# MB9BF16xx register map
File version: 1.0
Registers are 8-bit, read-write, reset 0x0 unless marked. A register's access mark holds for its fields unless they carry their own. Offsets are from the block's base; [hi:lo] are bit positions; {n}, {i} and the like mark numbered series.

## DAC0 — peripheral DAC0
Base 0x40033000
Same registers: DAC1 0x40033008
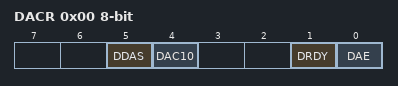
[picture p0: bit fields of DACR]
0x00 DACR
  [5] DDAS, [4] DAC10, [1] DRDY ro, [0] DAE
0x04 DADR 16-bit reset not defined
  [9:0] DA

## EXTI — peripheral EXTI
Base 0x40030000
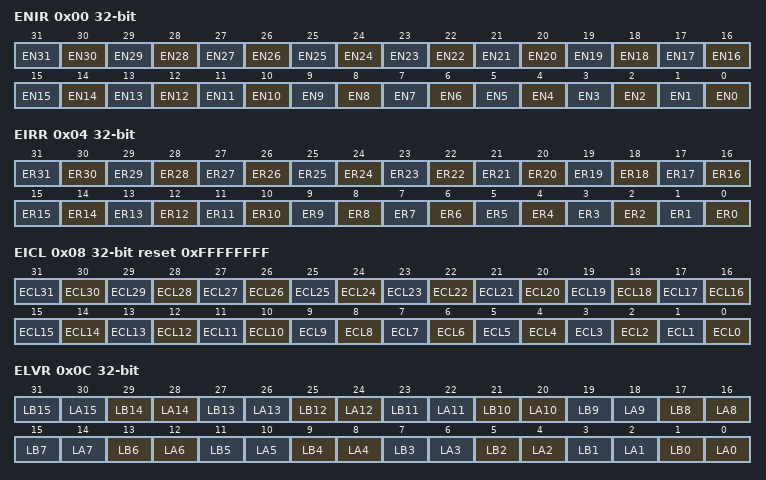
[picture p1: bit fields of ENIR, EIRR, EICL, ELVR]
0x00 ENIR 32-bit
  [n] EN{n} (n=0..31)
0x04 EIRR 32-bit ro reset not defined
  [n] ER{n} (n=0..31)
0x08 EICL 32-bit reset 0xFFFFFFFF
  [n] ECL{n} (n=0..31)
0x0C ELVR 32-bit
  [2n+1] LB{n} (n=0..15), [2n] LA{n} (n=0..15)
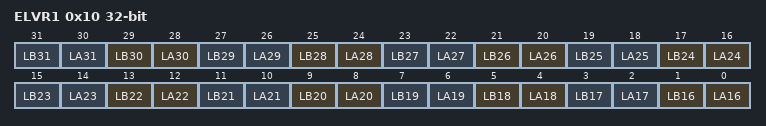
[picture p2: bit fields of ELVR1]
0x10 ELVR1 32-bit
  [2n-31] LB{n} (n=16..31), [2n-32] LA{n} (n=16..31)
0x14 NMIRR ro
  [0] NR
0x18 NMICL reset 0x1
  [0] NCL

## LVD — peripheral LVD
Base 0x40035000
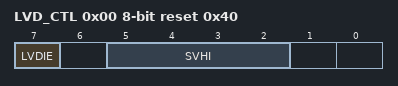
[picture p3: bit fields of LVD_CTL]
0x00 LVD_CTL reset 0x40
  [7] LVDIE, [5:2] SVHI
0x04 LVD_STR ro
  [7] LVDIR
0x08 LVD_CLR reset 0x80
  [7] LVDCL
0x0C LVD_RLR 32-bit reset 0x1
  [31:0] LVDLCK
0x10 LVD_STR2 ro reset 0x40
  [7] LVDIRDY

## DS — peripheral DS
Base 0x40035100
0x04 RCK_CTL reset 0x1
  [0] RTCCKE
0x700 PMD_CTL
  [0] RTCE
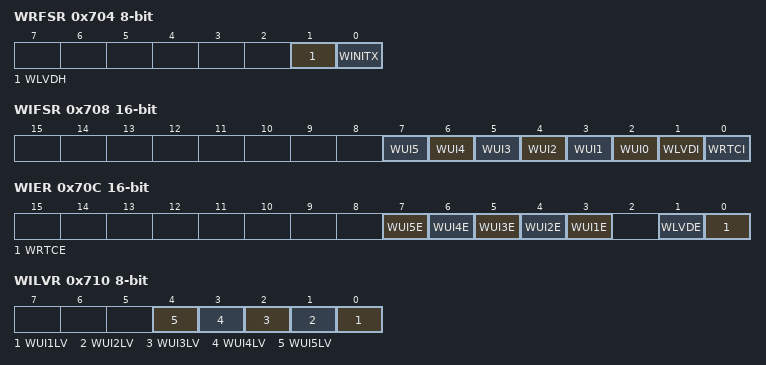
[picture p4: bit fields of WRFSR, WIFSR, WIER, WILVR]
0x704 WRFSR
  [1] WLVDH, [0] WINITX
0x708 WIFSR 16-bit ro
  [n+2] WUI{n} (n=0..5), [1] WLVDI, [0] WRTCI
0x70C WIER 16-bit
  [n+2] WUI{n}E (n=1..5), [1] WLVDE, [0] WRTCE
0x710 WILVR
  [n-1] WUI{n}LV (n=1..5)
0x714 DSRAMR
  [1:0] SRAMR
{0x7FF+i} BUR{i:02} (i=1..16)

## CRC — peripheral CRC
Base 0x40039000
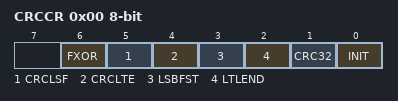
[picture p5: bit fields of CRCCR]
0x00 CRCCR
  [6] FXOR, [5] CRCLSF, [4] CRCLTE, [3] LSBFST, [2] LTLEND, [1] CRC32, [0] INIT
0x04 CRCINIT 32-bit reset 0xFFFFFFFF
  [31:0] D
0x08 CRCIN 32-bit
  [31:0] D
0x0C CRCR 32-bit ro reset 0xFFFFFFFF
  [31:0] D

## WC — peripheral WC
Base 0x4003A000
0x00 WCRD ro
  [5:0] CTR
0x01 WCRL
  [5:0] RLC
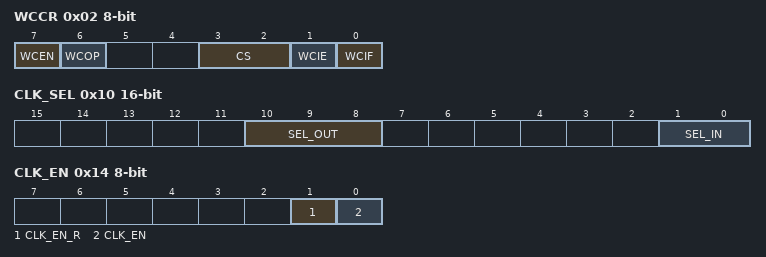
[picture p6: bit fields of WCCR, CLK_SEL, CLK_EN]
0x02 WCCR
  [7] WCEN, [6] WCOP ro, [3:2] CS, [1] WCIE, [0] WCIF
0x10 CLK_SEL 16-bit
  [10:8] SEL_OUT, [1:0] SEL_IN
0x14 CLK_EN
  [1] CLK_EN_R, [0] CLK_EN

## RTC — peripheral RTC
Base 0x4003B000
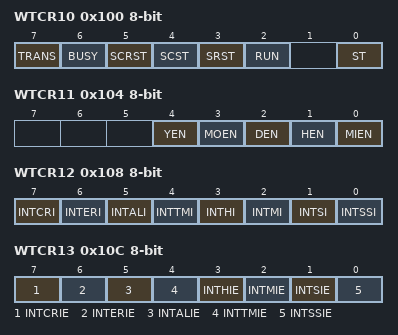
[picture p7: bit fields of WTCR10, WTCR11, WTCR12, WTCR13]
0x100 WTCR10
  [7] TRANS ro, [6] BUSY ro, [5] SCRST, [4] SCST, [3] SRST, [2] RUN ro, [0] ST
0x104 WTCR11
  [4] YEN, [3] MOEN, [2] DEN, [1] HEN, [0] MIEN
0x108 WTCR12
  [7] INTCRI, [6] INTERI, [5] INTALI, [4] INTTMI, [3] INTHI, [2] INTMI, [1] INTSI, [0] INTSSI
0x10C WTCR13
  [7] INTCRIE, [6] INTERIE, [5] INTALIE, [4] INTTMIE, [3] INTHIE, [2] INTMIE, [1] INTSIE, [0] INTSSIE
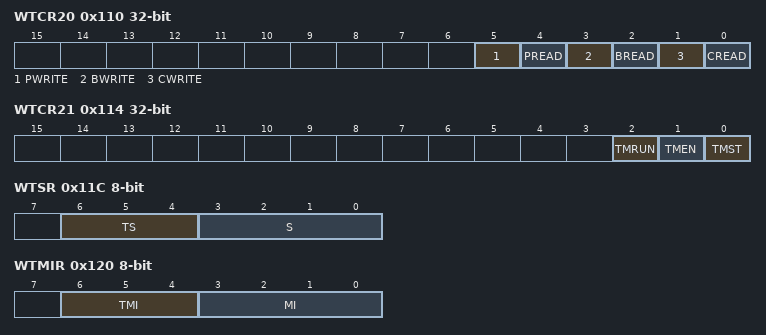
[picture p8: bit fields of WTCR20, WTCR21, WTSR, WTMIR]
0x110 WTCR20 32-bit
  [5] PWRITE, [4] PREAD, [3] BWRITE, [2] BREAD, [1] CWRITE, [0] CREAD
0x114 WTCR21 32-bit
  [2] TMRUN ro, [1] TMEN, [0] TMST
0x11C WTSR
  [6:4] TS, [3:0] S
0x120 WTMIR
  [6:4] TMI, [3:0] MI
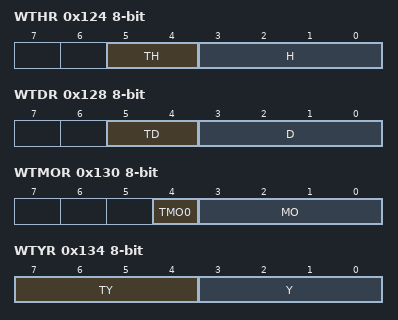
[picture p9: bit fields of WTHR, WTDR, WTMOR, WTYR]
0x124 WTHR
  [5:4] TH, [3:0] H
0x128 WTDR
  [5:4] TD, [3:0] D
0x12C WTDW
  [2:0] DW
0x130 WTMOR
  [4] TMO0, [3:0] MO
0x134 WTYR
  [7:4] TY, [3:0] Y
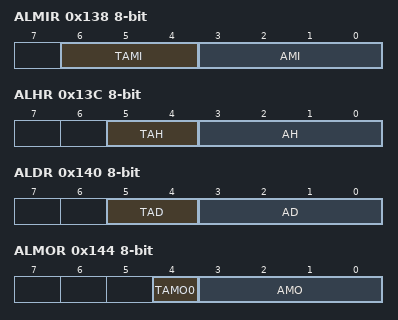
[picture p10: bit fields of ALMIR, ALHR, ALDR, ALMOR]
0x138 ALMIR
  [6:4] TAMI, [3:0] AMI
0x13C ALHR
  [5:4] TAH, [3:0] AH
0x140 ALDR
  [5:4] TAD, [3:0] AD
0x144 ALMOR
  [4] TAMO0, [3:0] AMO
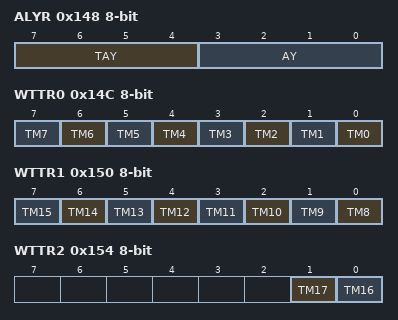
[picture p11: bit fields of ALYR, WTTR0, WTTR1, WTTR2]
0x148 ALYR
  [7:4] TAY, [3:0] AY
0x14C WTTR0
  [n] TM{n} (n=0..7)
0x150 WTTR1
  [n-8] TM{n} (n=8..15)
0x154 WTTR2
  [1] TM17, [0] TM16
0x158 WTCAL0
0x15C WTCAL1
  [1:0] WTCAL1
0x160 WTCALEN
  [0] WTCALEN
0x164 WTDIV
  [3:0] WTDIV
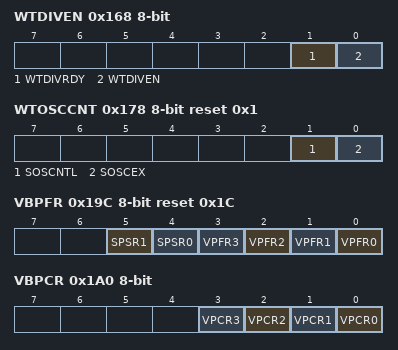
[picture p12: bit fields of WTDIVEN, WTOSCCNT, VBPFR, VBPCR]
0x168 WTDIVEN
  [1] WTDIVRDY ro, [0] WTDIVEN
0x16C WTCALPRD reset 0x13
  [5:0] WTCALPRD
0x170 WTCOSEL
  [0] WTCOSEL
0x174 VB_CLKDIV reset 0x7
  [7:0] DIV
0x178 WTOSCCNT reset 0x1
  [1] SOSCNTL, [0] SOSCEX
0x17C CCS reset 0x8
0x180 CCB reset 0x10
0x184 TRIM
0x188 BOOST reset 0x3
  [1:0] BOOST
0x18C EWKUP
  [0] WUP0
0x190 VDET reset 0x80
  [7] PON
0x194 FDET (reset mask 0x80)
0x198 HIBRST
  [0] HIBRST
0x19C VBPFR reset 0x1C
  [5] SPSR1, [4] SPSR0, [n] VPFR{n} (n=0..3)
0x1A0 VBPCR
  [n] VPCR{n} (n=0..3)
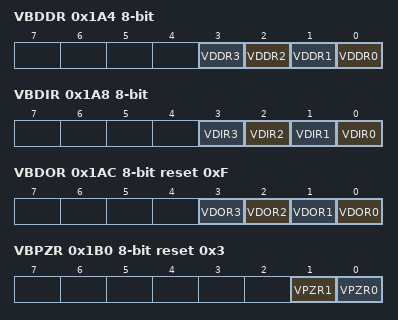
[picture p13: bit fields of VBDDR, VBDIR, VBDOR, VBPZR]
0x1A4 VBDDR
  [n] VDDR{n} (n=0..3)
0x1A8 VBDIR
  [n] VDIR{n} (n=0..3)
0x1AC VBDOR reset 0xF
  [n] VDOR{n} (n=0..3)
0x1B0 VBPZR reset 0x3
  [1] VPZR1, [0] VPZR0
{0x200+i} BREG{i:02} (i=0..9)
{0x20A+0x10*i} BREG{i}A (i=0..7)
{0x20B+0x10*i} BREG{i}B (i=0..7)
{0x20C+0x10*i} BREG{i}C (i=0..7)
{0x20D+0x10*i} BREG{i}D (i=0..7)
{0x20E+0x10*i} BREG{i}E (i=0..7)
{0x20F+0x10*i} BREG{i}F (i=0..7)
{0x206+i} BREG{i} (i=10..19)
{0x20C+i} BREG{i} (i=20..29)
{0x212+i} BREG{i} (i=30..39)
{0x218+i} BREG{i} (i=40..49)
{0x21E+i} BREG{i} (i=50..59)
{0x224+i} BREG{i} (i=60..69)
{0x22A+i} BREG{i} (i=70..79)

## LCR — peripheral LCR
Base 0x4003C000
0x00 LCR_PRSLD
  [5:0] LCR_PRSLD

## CLK_GATING — peripheral CLK_GATING
Base 0x4003C100
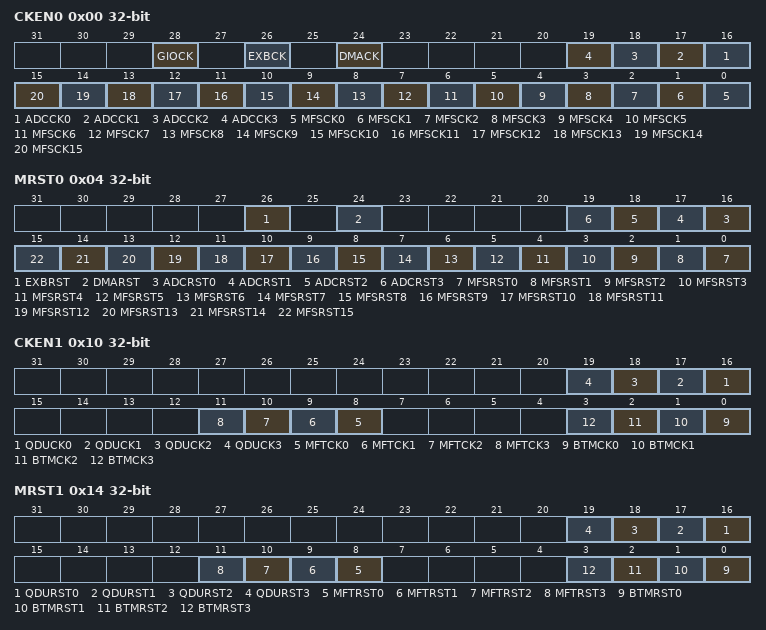
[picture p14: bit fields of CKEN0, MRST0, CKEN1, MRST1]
0x00 CKEN0 32-bit
  [28] GIOCK, [26] EXBCK, [24] DMACK, [n+16] ADCCK{n} (n=0..3), [n] MFSCK{n} (n=0..15)
0x04 MRST0 32-bit reset not defined
  [26] EXBRST, [24] DMARST, [n+16] ADCRST{n} (n=0..3), [n] MFSRST{n} (n=0..15)
0x10 CKEN1 32-bit
  [n+16] QDUCK{n} (n=0..3), [n+8] MFTCK{n} (n=0..3), [n] BTMCK{n} (n=0..3)
0x14 MRST1 32-bit reset not defined
  [n+16] QDURST{n} (n=0..3), [n+8] MFTRST{n} (n=0..3), [n] BTMRST{n} (n=0..3)
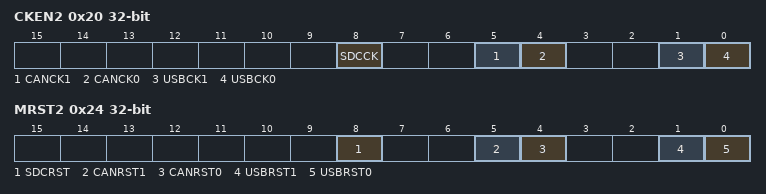
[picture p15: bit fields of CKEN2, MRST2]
0x20 CKEN2 32-bit (reset mask 0x30)
  [8] SDCCK, [5] CANCK1, [4] CANCK0, [1] USBCK1, [0] USBCK0
0x24 MRST2 32-bit reset not defined
  [8] SDCRST, [5] CANRST1, [4] CANRST0, [1] USBRST1, [0] USBRST0

## PLL_CONTROL — peripheral PLL_CONTROL
Base 0x4003C800
0x00 SSCTL1 32-bit (reset mask 0x31)
0x04 SSCTL2 32-bit (reset mask 0x3FF)

## EXBUS — peripheral EXBUS
Base 0x4003F000
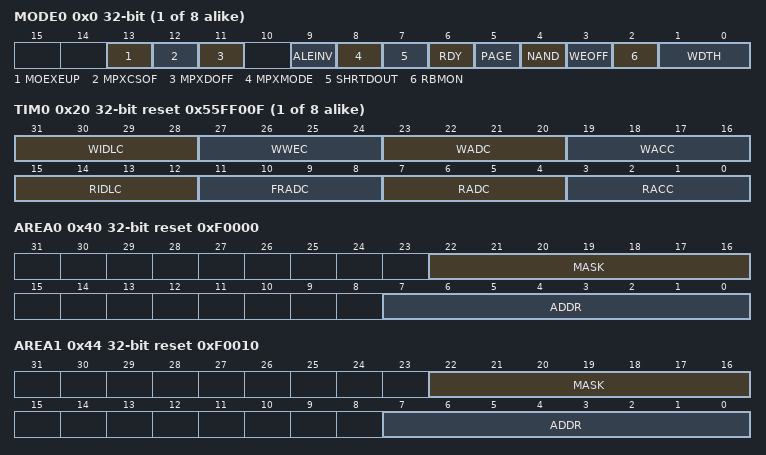
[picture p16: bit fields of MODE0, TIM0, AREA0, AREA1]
{0x0+4i} MODE{i} 32-bit (i=0..7)
  [13] MOEXEUP, [12] MPXCSOF, [11] MPXDOFF, [9] ALEINV, [8] MPXMODE, [7] SHRTDOUT, [6] RDY, [5] PAGE, [4] NAND, [3] WEOFF, [2] RBMON, [1:0] WDTH
{0x20+4i} TIM{i} 32-bit reset 0x55FF00F (i=0..7)
  [31:28] WIDLC, [27:24] WWEC, [23:20] WADC, [19:16] WACC, [15:12] RIDLC, [11:8] FRADC, [7:4] RADC, [3:0] RACC
0x40 AREA0 32-bit reset 0xF0000
  [22:16] MASK, [7:0] ADDR
0x44 AREA1 32-bit reset 0xF0010
  [22:16] MASK, [7:0] ADDR
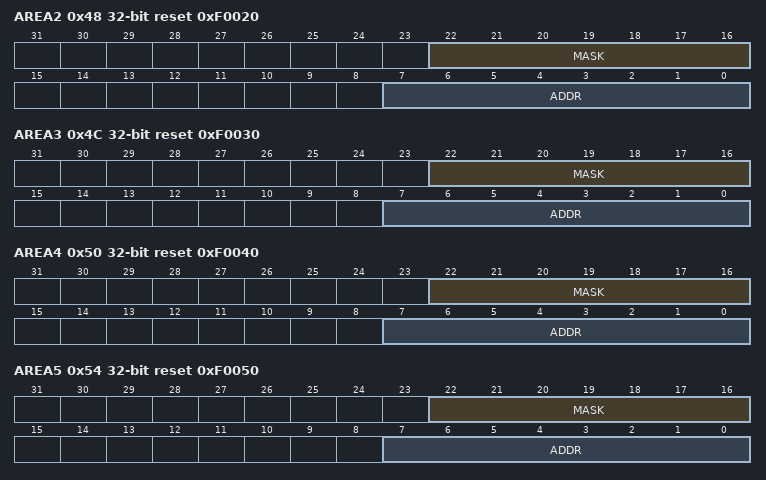
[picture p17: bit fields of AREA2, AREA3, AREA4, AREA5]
0x48 AREA2 32-bit reset 0xF0020
  [22:16] MASK, [7:0] ADDR
0x4C AREA3 32-bit reset 0xF0030
  [22:16] MASK, [7:0] ADDR
0x50 AREA4 32-bit reset 0xF0040
  [22:16] MASK, [7:0] ADDR
0x54 AREA5 32-bit reset 0xF0050
  [22:16] MASK, [7:0] ADDR
0x58 AREA6 32-bit reset 0xF0060
  [22:16] MASK, [7:0] ADDR
0x5C AREA7 32-bit reset 0xF0070
  [22:16] MASK, [7:0] ADDR
{0x60+4i} ATIM{i} 32-bit reset 0x45F (i=0..7)
  [11:8] ALEW, [7:4] ALES, [3:0] ALC
0x100 SMODE 32-bit reset 0x1300
  [16] MSDCLKOFF, [15:12] BASEL, [11:8] RASEL, [5:4] CASEL, [2] ROFF, [1] PDON, [0] SDON
0x104 REFTIM 32-bit reset 0x33
  [24] PREF, [23:16] NREF, [15:0] REFC
0x108 PWRDWN 32-bit
  [15:0] PDC
0x10C SDTIM 32-bit reset 0x420000
  [25:24] TDPL, [23:20] TREFC, [19:16] TRAS, [15:12] TRCD, [11:8] TRP, [7:4] TRC, [1:0] CL
0x110 SDCMD 32-bit
  [31] PEND ro, [20] SDCKE, [19] SDCS, [18] SDRAS, [17] SDCAS, [16] SDWE, [15:0] SDAD
0x200 MEMCERR 32-bit
  [3] SDION, [2] SFION, [1] SDER, [0] SFER
0x300 DCLKR 32-bit reset 0xF
  [4] MCLKON, [3:0] MDIV
0x304 EST 32-bit ro
  [0] WERR
0x308 WEAD 32-bit ro
  [31:0] ADDR
0x30C ESCLR 32-bit wo reset 0x1
  [0] WERRCLR
0x310 AMODE 32-bit reset 0x1
  [0] WAEN

## DMAC — peripheral DMAC
Base 0x40060000
0x00 DMACR 32-bit
  [31] DE, [30] DS, [28] PR, [27:24] DH
{0x10+0x10*i} DMACA{i} 32-bit (i=0..7)
  [31] EB, [30] PB, [29] ST, [28:23] IS, [19:16] BC, [15:0] TC
{0x14+0x10*i} DMACB{i} 32-bit (i=0..7)
  [29:28] MS, [27:26] TW, [25] FS, [24] FD, [23] RC, [22] RS, [21] RD, [20] EI, [19] CI, [18:16] SS, [0] EM
{0x18+0x10*i} DMACSA{i} 32-bit (i=0..7)
{0x1C+0x10*i} DMACDA{i} 32-bit (i=0..7)

## DSTC — peripheral DSTC
Base 0x40061000
0x00 DESTP 32-bit
0x04 HWDESP 32-bit
  [29:16] HWDESP, [7:0] CHANNEL
0x08 CMD reset 0x1
0x09 CFG reset 0x40
  [6:4] SWPR, [3] ESTE, [2] RBDIS, [1] ERINTE, [0] SWINTE
0x0A SWTR 16-bit
  [15] SWST ro, [14] SWREQ ro, [13:0] SWDESP
0x0C MONERS 32-bit
  [29:16] EDESP ro, [15:8] ECH ro, [6] EHS ro, [4] ESTOP ro, [3] DER ro, [2:0] EST ro
{0x10+4i} DREQENB{i} 32-bit (i=0..7)
{0x30+4i} HWINT{i} 32-bit (i=0..7)
{0x70+4i} DQMSK{i} 32-bit (i=0..7)
{0x90+4i} DQMSKCLR{i} 32-bit (i=0..7)

## SDIF — peripheral SDIF
Base 0x4006E000
0x00 DUMMY 32-bit reset not defined

## Notices in the file
Licence Terms
FUJITSU SEMICONDUCTOR LIMITED (gLICENSORh) hereby grants and
you (gLICENSEEh) hereby accept a non transferable, non-exclusive
licence to use and copy the deliverables (gDeliverablesh) solely for
the purpose of; (i) developing LICENSEEfs development tools and
distributing such development tools to third parties; (ii) generating
derivative representations of the Deliverables to develop and debug
software for LICENSORfs targeted devices or device series identified
within the Deliverables, (together the gPurposeh) under the following
terms and conditions:
1. Ownership.
The Deliverables are the property of LICENSOR. LICENSEE acquires no
right, title or interest in the Deliverables other than the licence
rights granted herein.
2. Use.
LICENSEE shall only be permitted to use the Deliverables for the
Purpose. LICENSEE shall not reverse engineer, decompile or
disassemble the Deliverables, in whole or in part.
3. Copies.
All copies of the Deliverables must bear the same notice(s) contained
on the original copies of the Deliverables.
4. No Warranty.
THE DELIVERABLES ARE PROVIDED gAS ISh AND ANY EXPRESS, IMPLIED OR
STATUTORY WARRANTIES, INCLUDING, BUT NOT LIMITED TO, THE IMPLIED
WARRANTIES OF MERCHANTABILITY, SATISFACTORY QUALITY AND FITNESS FOR
A PARTICULAR PURPOSE ARE DISCLAIMED.
IN NO EVENT SHALL LICENSOR BE LIABLE FOR ANY DIRECT, INDIRECT,
INCIDENTAL, SPECIAL, EXEMPLARY, OR CONSEQUENTIAL DAMAGES HOWEVER CAUSED
AND ON ANY THEORY OF LIABILITY, WHETHER IN CONTRACT, STRICT LIABILITY,
OR TORT (INCLUDING NEGLIGENCE OR OTHERWISE) ARISING IN ANY WAY OUT OF
THE USE OF THE DELIVERABLES, EVEN IF ADVISED OF THE POSSIBILITY OF SUCH
DAMAGE.
LICENSEE EXPRESSLY ASSUMES ALL LIABILITIES AND RISKS, FOR USE OR
OPERATION OF THE DELIVERABLES.
5.In the event that LICENSEE receives early access to the Deliverables,
LICENSEE acknowledges and agrees that;
(a) notwithstanding the licence grants above, LICENSEE shall only be
permitted to use the Deliverables solely internally for evaluation and
providing feedback to LICENSOR;
(b) except with respect to the limited licence grants in 5(a), LICENSEE
shall be subject to all of the terms and conditions set out above; and
(c) the Deliverables are confidential information and LICENSEE shall
maintain in confidence the Deliverables and apply security measures no
less stringent than the measures that LICENSEE applies to its own like
information, but not less than a reasonable degree of care, to prevent
unauthorised disclosure and use of the Deliverables.
